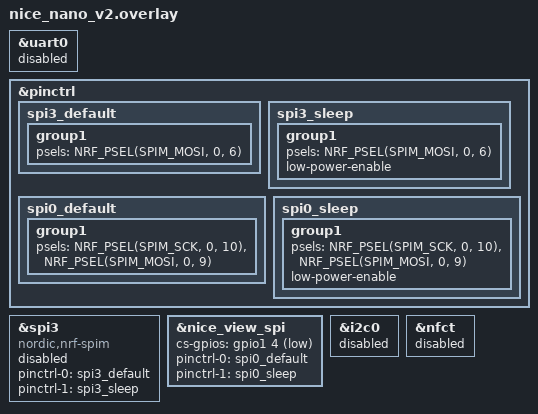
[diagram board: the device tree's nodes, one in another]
&uart0 {
    status = "disabled";
};
&pinctrl {
    spi3_default: spi3_default {
        group1 {
            psels = <NRF_PSEL(SPIM_MOSI, 0, 6)>;
        };
    };
    spi3_sleep: spi3_sleep {
        group1 {
            psels = <NRF_PSEL(SPIM_MOSI, 0, 6)>;
            low-power-enable;
        };
    };
    spi0_default: spi0_default {
        group1 {
            psels = <NRF_PSEL(SPIM_SCK, 0, 10)>,
                    <NRF_PSEL(SPIM_MOSI, 0, 9)>;
        };
    };
    spi0_sleep: spi0_sleep {
        group1 {
            psels = <NRF_PSEL(SPIM_SCK, 0, 10)>,
                    <NRF_PSEL(SPIM_MOSI, 0, 9)>;
            low-power-enable;
        };
    };
};
&spi3 {
    compatible = "nordic,nrf-spim";
    status = "disabled";
    pinctrl-0 = <&spi3_default>;
    pinctrl-1 = <&spi3_sleep>;
    pinctrl-names = "default", "sleep";
};
&nice_view_spi {
    cs-gpios = <&gpio1 4 GPIO_ACTIVE_LOW>;
    pinctrl-0 = <&spi0_default>;
    pinctrl-1 = <&spi0_sleep>;
    pinctrl-names = "default", "sleep";
};
&i2c0 {
    status = "disabled";
};
&nfct {
    status = "disabled";
};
